# PIC32CZ4010CA80208 register map
Vendor: Microchip Technology; Series: PIC32CZCA80; File version: 0
CPU: CM7 r1p1, little endian, MPU, FPU, double-precision FPU, I-cache, D-cache, ITCM, DTCM, 3 interrupt priority bits, 222 interrupts
Registers are 32-bit, read-write, reset 0x0 unless marked. A register's access mark holds for its fields unless they carry their own. Offsets are from the block's base; [hi:lo] are bit positions; {n}, {i} and the like mark numbered series; 'fields as' and 'values as' point back to an identical list.

## NVIC — Nested Vectored Interrupt Controller
Base 0xE000E000
0x04 ICTR ro — Interrupt Controller Type Register
  [3:0] INTLINESNUM — Number of 32-interrupt groups - 1
{0x100+4i} ISER[{i}] (i=0..6) — Interrupt Set Enable Register
  [31:0] SETENA — Interrupt set enable bits
{0x180+4i} ICER[{i}] (i=0..6) — Interrupt Clear Enable Register
  [31:0] CLRENA — Interrupt clear-enable bits
{0x200+4i} ISPR[{i}] (i=0..6) — Interrupt Set Pending Register
  [31:0] SETPEND — Interrupt set-pending bits
{0x280+4i} ICPR[{i}] (i=0..6) — Interrupt Clear Pending Register
  [31:0] CLRPEND — Interrupt clear-pending bits
{0x300+4i} IABR[{i}] (i=0..6) ro — Interrupt Active Bit Register
  [31:0] ACTIVE — Interrupt active bits
{0x400+i} IPR[{i}] (i=0..55) 8-bit — Interrupt Priority Register n
  [2:0] PRI0 — Priority of interrupt n

## OSC32KCTRL — 32kHz Oscillators Control
Base 0x44042000
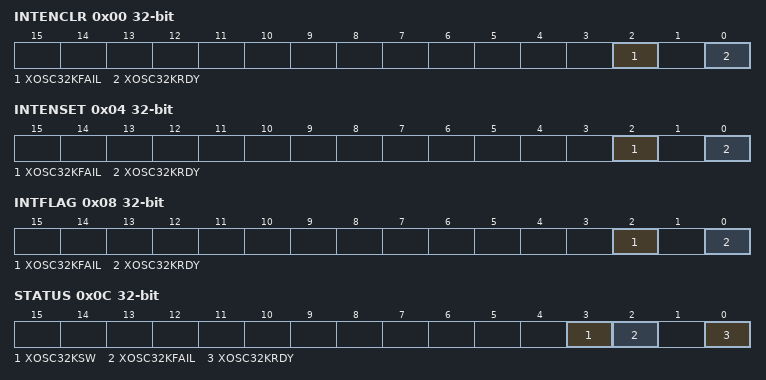
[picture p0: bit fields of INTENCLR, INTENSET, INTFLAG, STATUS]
0x00 INTENCLR write-1-clears — Interrupt Enable Clear
  [2] XOSC32KFAIL — XOSC32K Clock Failure Detector Interrupt Enable
  [0] XOSC32KRDY — XOSC32K Ready Interrupt Enable
0x04 INTENSET write-1-sets — Interrupt Enable Set
  fields as INTENCLR
0x08 INTFLAG write-1-clears — Interrupt Flag Status and Clear
  [2] XOSC32KFAIL — XOSC32K Clock Failure Detector
  [0] XOSC32KRDY — XOSC32K Ready
0x0C STATUS ro — Power and Clocks Status
  [3] XOSC32KSW — XOSC32K Clock switch
  [2] XOSC32KFAIL — XOSC32K Clock Failure Detector
  [0] XOSC32KRDY — XOSC32K Ready
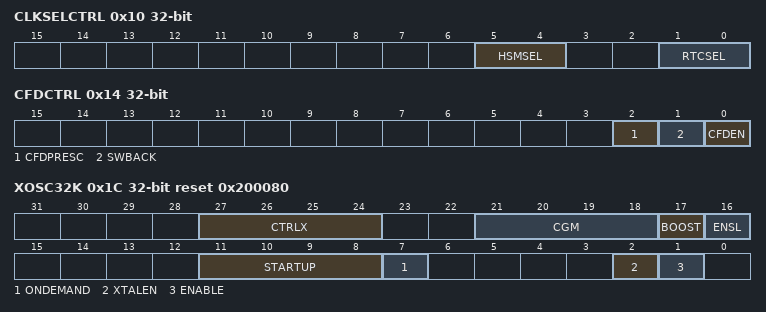
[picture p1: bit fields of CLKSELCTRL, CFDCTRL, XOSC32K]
0x10 CLKSELCTRL — Clock Selection Control
  [5:4] HSMSEL — HSM Clock Selection
    0=ULP32K (32.768kHz from 32kHz internal ULP oscillator); 2=XOSC32K (32.768kHz from 32.768kHz external crystal oscillator)
  [1:0] RTCSEL — RTC Clock Selection
    0=ULP32K (32.768kHz from 32kHz internal ULP oscillator); 1=ULP1K (1.024kHz from 32kHz internal ULP oscillator); 2=XOSC32K (32.768kHz from 32.768kHz external crystal oscillator); 3=XOSC1K (1.024kHz from 32.768kHz internal oscillator)
0x14 CFDCTRL — Clock Failure Detector Control
  [2] CFDPRESC — Clock Failure Detector Prescaler
  [1] SWBACK — Clock Switch Back
  [0] CFDEN — Clock Failure Detector Enable
0x18 EVCTRL — Event Control
  [0] CFDEO — Clock Failure Detector Event Output Enable
0x1C XOSC32K reset 0x200080 — 32kHz External Crystal Oscillator (XOSC32K) Control
  [27:24] CTRLX — Extended Control
  [21:18] CGM — Control Gain Mode
    0=The lower Control Gain Mode value; {v}=A higher Control Gain Mode value than CGM{v-1} (v=1..14); 15=The highest Control Gain Mode value
  [17] BOOST — Gain Boost
  [16] ENSL — Enable Servo Loop
  [11:8] STARTUP — Startup Mode
    0=1CYCLE (1 ULP clock cycle); 1=16CYCLES (16 ULP clock cycles); 2=32CYCLES (32 ULP clock cycles); 3=2048CYCLES (2048 ULP clock cycles); 4=4096CYCLES (4096 ULP clock cycles); 5=8192CYCLES (8192 ULP clock cycles); 6=16384CYCLES (16384 ULP clock cycles); 7=32768CYCLES (32768 ULP clock cycles); 8=65536CYCLES (65536 ULP clock cycles); 9=131072CYCLES (131072 ULP clock cycles); 10=262144CYCLES (262144 ULP clock cycles)
  [7] ONDEMAND — On Demand Mode
  [2] XTALEN — Crystal Oscillator Enable
  [1] ENABLE — Oscillator Enable

## PAC — Peripheral Access Controller
Base 0x44810000
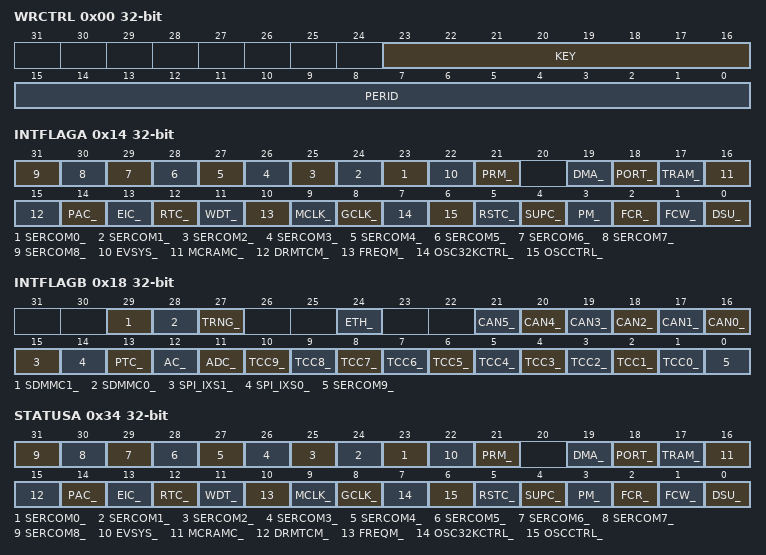
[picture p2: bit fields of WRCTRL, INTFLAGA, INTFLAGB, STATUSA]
0x00 WRCTRL — Write control
  [23:16] KEY — Peripheral access control key
    0=OFF (No action); 1=CLR (Clear protection); 2=SET (Set protection); 3=SETLCK (Set and lock protection)
  [15:0] PERID — Peripheral identifier
0x04 EVCTRL 8-bit — Event control
  [0] ERREO — Peripheral acess error event output
0x08 INTENCLR 8-bit write-1-clears — Interrupt enable clear
  [0] ERR — Peripheral access error interrupt disable
0x09 INTENSET 8-bit write-1-sets — Interrupt enable set
  [0] ERR — Peripheral access error interrupt enable
0x10 INTFLAGAHB write-1-clears — Bridge interrupt flag status
0x14 INTFLAGA write-1-clears — Peripheral interrupt flag status - Bridge A
  [n+23] SERCOM{n}_ (n=0..8), [22] EVSYS_, [21] PRM_, [19] DMA_, [18] PORT_, [17] TRAM_, [16] MCRAMC_, [15] DRMTCM_, [14] PAC_, [13] EIC_, [12] RTC_, [11] WDT_, [10] FREQM_, [9] MCLK_, [8] GCLK_, [7] OSC32KCTRL_, [6] OSCCTRL_, [5] RSTC_, [4] SUPC_, [3] PM_, [2] FCR_, [1] FCW_, [0] DSU_
0x18 INTFLAGB write-1-clears — Peripheral interrupt flag status - Bridge B
  [29] SDMMC1_, [28] SDMMC0_, [27] TRNG_, [24] ETH_, [n+16] CAN{n}_ (n=0..5), [15] SPI_IXS1_, [14] SPI_IXS0_, [13] PTC_, [12] AC_, [11] ADC_, [n+1] TCC{n}_ (n=0..9), [0] SERCOM9_
0x1C INTFLAGC write-1-clears — Peripheral interrupt flag status - Bridge C
  [2] MLB_
0x34 STATUSA ro — Peripheral write protection status - Bridge A
  [n+23] SERCOM{n}_ (n=0..8) — SERCOM{n} APB Protect Enable
  [22] EVSYS_ — EVSYS APB Protect Enable
  [21] PRM_ — PRM APB Protect Enable
  [19] DMA_ — DMA APB Protect Enable
  [18] PORT_ — PORT APB Protect Enable
  [17] TRAM_ — TRAM APB Protect Enable
  [16] MCRAMC_ — MCRAMC APB Protect Enable
  [15] DRMTCM_ — DRMTCM APB Protect Enable
  [14] PAC_ — PAC APB Protect Enable
  [13] EIC_ — EIC APB Protect Enable
  [12] RTC_ — RTC APB Protect Enable
  [11] WDT_ — WDT APB Protect Enable
  [10] FREQM_ — FREQM APB Protect Enable
  [9] MCLK_ — MCLK APB Protect Enable
  [8] GCLK_ — GCLK APB Protect Enable
  [7] OSC32KCTRL_ — OSC32KCTRL APB Protect Enable
  [6] OSCCTRL_ — OSCCTRL APB Protect Enable
  [5] RSTC_ — RSTC APB Protect Enable
  [4] SUPC_ — SUPC APB Protect Enable
  [3] PM_ — PM APB Protect Enable
  [2] FCR_ — FCR APB Protect Enable
  [1] FCW_ — FCW APB Protect Enable
  [0] DSU_ — DSU APB Protect Enable
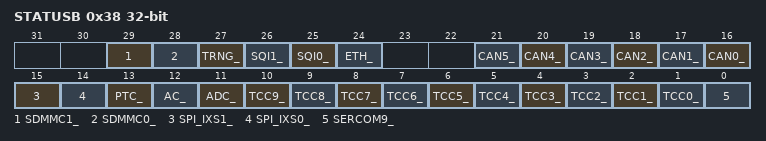
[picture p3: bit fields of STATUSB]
0x38 STATUSB ro — Peripheral write protection status - Bridge B
  [29] SDMMC1_ — SDMMC1 APB Protect Enable
  [28] SDMMC0_ — SDMMC0 APB Protect Enable
  [27] TRNG_ — TRNG APB Protect Enable
  [26] SQI1_ — SQI1 APB Protect Enable
  [25] SQI0_ — SQI0 APB Protect Enable
  [24] ETH_ — ETH APB Protect Enable
  [n+16] CAN{n}_ (n=0..5) — CAN{n} APB Protect Enable
  [15] SPI_IXS1_ — SPI_IXS1 APB Protect Enable
  [14] SPI_IXS0_ — SPI_IXS0 APB Protect Enable
  [13] PTC_ — PTC APB Protect Enable
  [12] AC_ — AC APB Protect Enable
  [11] ADC_ — ADC APB Protect Enable
  [n+1] TCC{n}_ (n=0..9) — TCC{n} APB Protect Enable
  [0] SERCOM9_ — SERCOM9 APB Protect Enable
0x3C STATUSC ro reset 0x38 — Peripheral write protection status - Bridge C
  [2] MLB_ — MLB APB Protect Enable

## Notices in the file
Copyright (c) 2026 Microchip Technology Inc.
SPDX-License-Identifier: Apache-2.0
Licensed under the Apache License, Version 2.0 (the "License");
you may not use this file except in compliance with the License.
You may obtain a copy of the License at
http://www.apache.org/licenses/LICENSE-2.0
Unless required by applicable law or agreed to in writing, software
distributed under the License is distributed on an "AS IS" BASIS,
WITHOUT WARRANTIES OR CONDITIONS OF ANY KIND, either express or implied.
See the License for the specific language governing permissions and
limitations under the License.
